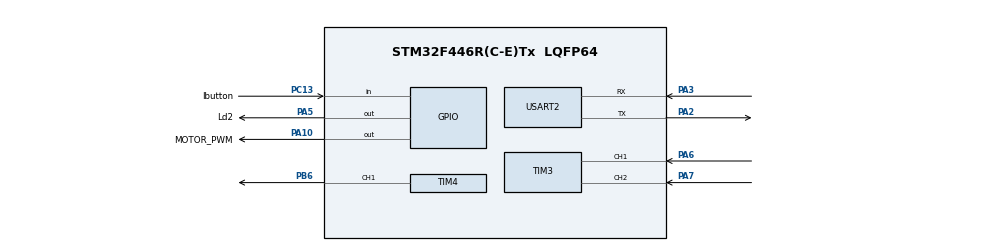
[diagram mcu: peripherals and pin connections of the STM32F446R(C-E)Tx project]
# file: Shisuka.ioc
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Mcu.Family=STM32F4
Mcu.Name=STM32F446R(C-E)Tx
Mcu.Package=LQFP64
NVIC.PriorityGroup=NVIC_PRIORITYGROUP_4
NVIC.TIM4_IRQn=true\:0\:0\:false\:false\:true\:true\:true
NVIC.USART2_IRQn=true\:0\:0\:false\:false\:true\:true\:true
PA10.GPIO_Label=MOTOR_PWM
PA10.Signal=GPIO_Output
PA2.Mode=Asynchronous
PA2.Signal=USART2_TX
PA3.Mode=Asynchronous
PA3.Signal=USART2_RX
PA5.GPIO_Label=Ld2
PA5.Signal=GPIO_Output
PA6.GPIO_PuPd=GPIO_PULLUP
PA6.Signal=S_TIM3_CH1
PA7.GPIO_PuPd=GPIO_PULLUP
PA7.Signal=S_TIM3_CH2
PB6.Signal=S_TIM4_CH1
PC13.GPIO_Label=Ibutton
PC13.GPIO_PuPd=GPIO_PULLUP
PC13.Signal=GPIO_Input
ProjectManager.HeapSize=0x200
ProjectManager.StackSize=0x400
ProjectManager.TargetToolchain=STM32CubeIDE
RCC.CortexFreq_Value=16000000
RCC.USBFreq_Value=96000000
RCC.VCOOutputFreq_Value=192000000
SH.S_TIM3_CH1.0=TIM3_CH1,Encoder_Interface
SH.S_TIM3_CH2.0=TIM3_CH2,Encoder_Interface
SH.S_TIM4_CH1.0=TIM4_CH1,PWM Generation1 CH1
TIM3.EncoderMode=TIM_ENCODERMODE_TI1
TIM4.Channel-PWM\ Generation1\ CH1=TIM_CHANNEL_1
TIM4.Period=1000
TIM4.Prescaler=84
USART2.VirtualMode=VM_ASYNC
board=custom

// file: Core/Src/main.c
/* USER CODE BEGIN Header */
/**
  ******************************************************************************
  * @file           : main.c
  * @brief          : Main program body
  ******************************************************************************
  * @attention
  *
  * <h2><center>&copy; Copyright (c) 2020 STMicroelectronics.
  * All rights reserved.</center></h2>
  *
  * This software component is licensed by ST under BSD 3-Clause license,
  * the "License"; You may not use this file except in compliance with the
  * License. You may obtain a copy of the License at:
  *                        opensource.org/licenses/BSD-3-Clause
  *
  ******************************************************************************
  */
/* USER CODE END Header */
#include "main.h"

/* USER CODE BEGIN Includes */
#include "stdio.h"
/* USER CODE END Includes */

TIM_HandleTypeDef htim3;
TIM_HandleTypeDef htim4;

UART_HandleTypeDef huart2;

void SystemClock_Config(void);
static void MX_GPIO_Init(void);
static void MX_TIM3_Init(void);
static void MX_TIM4_Init(void);
static void MX_USART2_UART_Init(void);

/* USER CODE BEGIN 0 */

char output_buf[50];
uint16_t str_num;

/* USER CODE END 0 */

int main(void)
{

  /* MCU Configuration--------------------------------------------------------*/

  /* Reset of all peripherals, Initializes the Flash interface and the Systick. */
  HAL_Init();

  /* Configure the system clock */
  SystemClock_Config();

  /* Initialize all configured peripherals */
  MX_GPIO_Init();
  MX_TIM3_Init();
  MX_TIM4_Init();
  MX_USART2_UART_Init();

  /* Infinite loop */
  /* USER CODE BEGIN WHILE */

  HAL_TIM_PWM_Start(&htim4, TIM_CHANNEL_1);
  __HAL_TIM_SET_COMPARE(&htim4, TIM_CHANNEL_1, 100);

  HAL_TIM_Encoder_Start(&htim3, TIM_CHANNEL_ALL);
  int32_t encoder_value = htim3.Instance -> CNT;

  str_num = sprintf(output_buf, "Hello");
  HAL_UART_Transmit_IT(&huart2, output_buf, str_num);

  while (1)
  {
    /* USER CODE END WHILE */

    /* USER CODE BEGIN 3 */
	  encoder_value = htim3.Instance->CNT;
	  str_num = sprintf(output_buf, "Encoder value = %ld\r\n", encoder_value);
	  HAL_UART_Transmit_IT(&huart2, output_buf, str_num);
  }
  /* USER CODE END 3 */
}

void SystemClock_Config(void)
{
  RCC_OscInitTypeDef RCC_OscInitStruct = {0};
  RCC_ClkInitTypeDef RCC_ClkInitStruct = {0};

  /** Configure the main internal regulator output voltage
  */
  __HAL_RCC_PWR_CLK_ENABLE();
  __HAL_PWR_VOLTAGESCALING_CONFIG(PWR_REGULATOR_VOLTAGE_SCALE3);
  /** Initializes the RCC Oscillators according to the specified parameters
  * in the RCC_OscInitTypeDef structure.
  */
  RCC_OscInitStruct.OscillatorType = RCC_OSCILLATORTYPE_HSI;
  RCC_OscInitStruct.HSIState = RCC_HSI_ON;
  RCC_OscInitStruct.HSICalibrationValue = RCC_HSICALIBRATION_DEFAULT;
  RCC_OscInitStruct.PLL.PLLState = RCC_PLL_NONE;
  if (HAL_RCC_OscConfig(&RCC_OscInitStruct) != HAL_OK)
  {
    Error_Handler();
  }
  /** Initializes the CPU, AHB and APB buses clocks
  */
  RCC_ClkInitStruct.ClockType = RCC_CLOCKTYPE_HCLK|RCC_CLOCKTYPE_SYSCLK
                              |RCC_CLOCKTYPE_PCLK1|RCC_CLOCKTYPE_PCLK2;
  RCC_ClkInitStruct.SYSCLKSource = RCC_SYSCLKSOURCE_HSI;
  RCC_ClkInitStruct.AHBCLKDivider = RCC_SYSCLK_DIV1;
  RCC_ClkInitStruct.APB1CLKDivider = RCC_HCLK_DIV1;
  RCC_ClkInitStruct.APB2CLKDivider = RCC_HCLK_DIV1;

  if (HAL_RCC_ClockConfig(&RCC_ClkInitStruct, FLASH_LATENCY_0) != HAL_OK)
  {
    Error_Handler();
  }
}

static void MX_TIM3_Init(void)
{

  TIM_Encoder_InitTypeDef sConfig = {0};
  TIM_MasterConfigTypeDef sMasterConfig = {0};

  htim3.Instance = TIM3;
  htim3.Init.Prescaler = 0;
  htim3.Init.CounterMode = TIM_COUNTERMODE_UP;
  htim3.Init.Period = 65535;
  htim3.Init.ClockDivision = TIM_CLOCKDIVISION_DIV1;
  htim3.Init.AutoReloadPreload = TIM_AUTORELOAD_PRELOAD_DISABLE;
  sConfig.EncoderMode = TIM_ENCODERMODE_TI1;
  sConfig.IC1Polarity = TIM_ICPOLARITY_RISING;
  sConfig.IC1Selection = TIM_ICSELECTION_DIRECTTI;
  sConfig.IC1Prescaler = TIM_ICPSC_DIV1;
  sConfig.IC1Filter = 0;
  sConfig.IC2Polarity = TIM_ICPOLARITY_RISING;
  sConfig.IC2Selection = TIM_ICSELECTION_DIRECTTI;
  sConfig.IC2Prescaler = TIM_ICPSC_DIV1;
  sConfig.IC2Filter = 0;
  if (HAL_TIM_Encoder_Init(&htim3, &sConfig) != HAL_OK)
  {
    Error_Handler();
  }
  sMasterConfig.MasterOutputTrigger = TIM_TRGO_RESET;
  sMasterConfig.MasterSlaveMode = TIM_MASTERSLAVEMODE_DISABLE;
  if (HAL_TIMEx_MasterConfigSynchronization(&htim3, &sMasterConfig) != HAL_OK)
  {
    Error_Handler();
  }

}

static void MX_TIM4_Init(void)
{

  TIM_MasterConfigTypeDef sMasterConfig = {0};
  TIM_OC_InitTypeDef sConfigOC = {0};

  htim4.Instance = TIM4;
  htim4.Init.Prescaler = 84;
  htim4.Init.CounterMode = TIM_COUNTERMODE_UP;
  htim4.Init.Period = 1000;
  htim4.Init.ClockDivision = TIM_CLOCKDIVISION_DIV1;
  htim4.Init.AutoReloadPreload = TIM_AUTORELOAD_PRELOAD_DISABLE;
  if (HAL_TIM_PWM_Init(&htim4) != HAL_OK)
  {
    Error_Handler();
  }
  sMasterConfig.MasterOutputTrigger = TIM_TRGO_RESET;
  sMasterConfig.MasterSlaveMode = TIM_MASTERSLAVEMODE_DISABLE;
  if (HAL_TIMEx_MasterConfigSynchronization(&htim4, &sMasterConfig) != HAL_OK)
  {
    Error_Handler();
  }
  sConfigOC.OCMode = TIM_OCMODE_PWM1;
  sConfigOC.Pulse = 0;
  sConfigOC.OCPolarity = TIM_OCPOLARITY_HIGH;
  sConfigOC.OCFastMode = TIM_OCFAST_DISABLE;
  if (HAL_TIM_PWM_ConfigChannel(&htim4, &sConfigOC, TIM_CHANNEL_1) != HAL_OK)
  {
    Error_Handler();
  }
  HAL_TIM_MspPostInit(&htim4);

}

static void MX_USART2_UART_Init(void)
{

  huart2.Instance = USART2;
  huart2.Init.BaudRate = 115200;
  huart2.Init.WordLength = UART_WORDLENGTH_8B;
  huart2.Init.StopBits = UART_STOPBITS_1;
  huart2.Init.Parity = UART_PARITY_NONE;
  huart2.Init.Mode = UART_MODE_TX_RX;
  huart2.Init.HwFlowCtl = UART_HWCONTROL_NONE;
  huart2.Init.OverSampling = UART_OVERSAMPLING_16;
  if (HAL_UART_Init(&huart2) != HAL_OK)
  {
    Error_Handler();
  }

}

static void MX_GPIO_Init(void)
{
  GPIO_InitTypeDef GPIO_InitStruct = {0};

  /* GPIO Ports Clock Enable */
  __HAL_RCC_GPIOC_CLK_ENABLE();
  __HAL_RCC_GPIOA_CLK_ENABLE();
  __HAL_RCC_GPIOB_CLK_ENABLE();

  /*Configure GPIO pin Output Level */
  HAL_GPIO_WritePin(GPIOA, Ld2_Pin|MOTOR_PWM_Pin, GPIO_PIN_RESET);

  /*Configure GPIO pin : Ibutton_Pin */
  GPIO_InitStruct.Pin = Ibutton_Pin;
  GPIO_InitStruct.Mode = GPIO_MODE_INPUT;
  GPIO_InitStruct.Pull = GPIO_PULLUP;
  HAL_GPIO_Init(Ibutton_GPIO_Port, &GPIO_InitStruct);

  /*Configure GPIO pins : Ld2_Pin MOTOR_PWM_Pin */
  GPIO_InitStruct.Pin = Ld2_Pin|MOTOR_PWM_Pin;
  GPIO_InitStruct.Mode = GPIO_MODE_OUTPUT_PP;
  GPIO_InitStruct.Pull = GPIO_NOPULL;
  GPIO_InitStruct.Speed = GPIO_SPEED_FREQ_LOW;
  HAL_GPIO_Init(GPIOA, &GPIO_InitStruct);

}

void Error_Handler(void)
{
}

/************************ (C) COPYRIGHT STMicroelectronics *****END OF FILE****/
